# N569S register map
File version: 1.0
Registers are 32-bit, read-write, reset 0x0 unless marked. A register's access mark holds for its fields unless they carry their own. Offsets are from the block's base; [hi:lo] are bit positions.

## UART0 — UART0 Register Map
Base 0x40060000
0x00 UART_DAT ro reset not defined — UART0 Receive/Transmit FIFO Register.
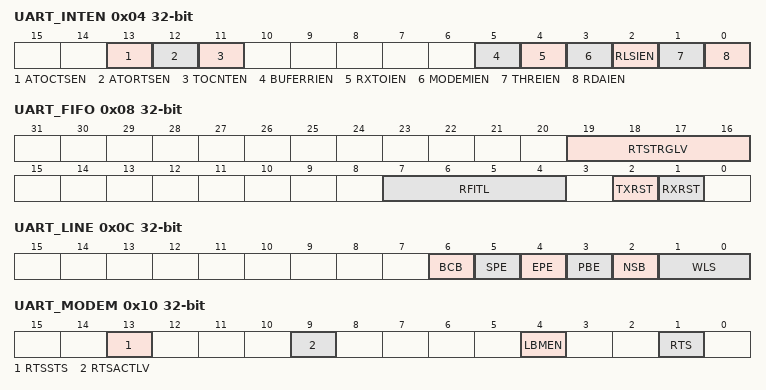
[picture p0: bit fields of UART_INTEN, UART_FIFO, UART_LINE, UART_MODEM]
0x04 UART_INTEN — UART0 Interrupt Enable Register.
  [13] ATOCTSEN — CTS Auto Flow Control Enable. When CTS auto-flow is enabled, the UART will send data to external device when CTS input is asserted (UART will not send data to device until CTS is asserted).
    0=Disable CTS auto flow control; 1=Enable
  [12] ATORTSEN — RTS Auto Flow Control Enable. When RTS auto-flow is enabled, if the number of bytes in the Rx FIFO equals UART_FIFO.RTSTRGLV, the UART will de-assert the RTS signal.
    0=Disable RTS auto flow control; 1=Enable
  [11] TOCNTEN — Time-out Counter Enable
    0=Disable Time-out counter; 1=Enable
  [5] BUFERRIEN — Buffer Error Interrupt Enable
    0=Mask off BUFERRINT; 1=Enable IBUFERRINT
  [4] RXTOIEN — Receive Time Out Interrupt Enable
    0=Mask off RXTOINT; 1=Enable RXTOINT
  [3] MODEMIEN — Modem Status Interrupt Enable
    0=Mask off MODEMINT; 1=Enable MODEMINT
  [2] RLSIEN — Receive Line Status Interrupt Enable
    0=Mask off RLSINT; 1=Enable RLSINT
  [1] THREIEN — Transmit FIFO Register Empty Interrupt Enable
    0=Mask off THERINT; 1=Enable THERINT
  [0] RDAIEN — Receive Data Available Interrupt Enable
    0=Mask off RDAINT; 1=Enable RDAINT
0x08 UART_FIFO — UART0 FIFO Control Register.
  [19:16] RTSTRGLV — RTS Trigger Level for Auto-flow Control
  [7:4] RFITL — Receive FIFO Interrupt (RDAINT) Trigger Level
  [2] TXRST — Transmit FIFO Reset. When TXRST is set, all the bytes in the transmit FIFO are cleared and transmit internal state machine is reset. Note: This bit will auto-clear after 3 UART engine clock cycles.
    0=Writing 0 to this bit has no effect; 1=Writing 1 to this bit will reset the transmit internal state machine and pointers
  [1] RXRST — Receive FIFO Reset. When RXRST is set, all the bytes in the receive FIFO are cleared and receive internal state machine is reset. Note: This bit will auto-clear after 3 UART engine clock cycles.
    0=Writing 0 to this bit has no effect; 1=Writing 1 to this bit will reset the receiving internal state machine and pointers
0x0C UART_LINE — UART0 Line Control Register.
  [6] BCB — Break Control Bit. When this bit is set to logic 1, the serial data output (Tx) is forced to the 'Space' state (logic 0). Normal condition is serial data output is 'Mark' state. This bit acts only on Tx and has no effect on the transmitter logic.
  [5] SPE — Stick Parity Enable
    0=Disable stick parity; 1=When bits PBE and SPE are set 'Stick Parity' is enabled. If EPE=0 the parity bit is transmitted and checked as always set, if EPE=1, the parity bit is transmitted and checked as always cleared
  [4] EPE — Even Parity Enable. This bit has effect only when PBE (parity bit enable) is set.
    0=Odd number of logic 1's are transmitted or checked in the data word and parity bits; 1=Even number of logic 1's are transmitted or checked in the data word and parity bits
  [3] PBE — Parity Bit Enable
    0=Parity bit is not generated (transmit data) or checked (receive data) during transfer; 1=Parity bit is generated or checked between the "last data word bit" and "stop bit" of the serial data
  [2] NSB — Number of STOP bits
    0=One "STOP bit" is generated after the transmitted data; 1=Two "STOP bits" are generated when 6-, 7- and 8-bit word length is selected; One and a half "STOP bits" are generated in the transmitted data when 5-bit word length is selected;
  [1:0] WLS — Word Length Select
0x10 UART_MODEM — UART0 Modem Control Register.
  [13] RTSSTS ro — RTS Pin State (Read Only). This bit is the pin status of RTS.
  [9] RTSACTLV — Request-to-send (RTS) Active Trigger Level. This bit can change the RTS trigger level.
    0=RTS is active low level; 1=RTS is active high level
  [4] LBMEN — Loopback Mode Enable
    0=Disable; 1=Enable
  [1] RTS — RTS (Request-to-send) Signal
    0=Drive RTS inactive ( = ~RTSACTLV); 1=Drive RTS active ( = RTSACTLV)
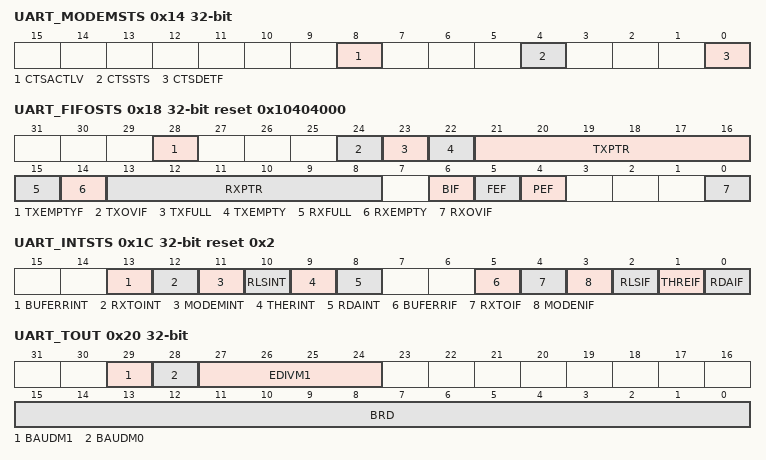
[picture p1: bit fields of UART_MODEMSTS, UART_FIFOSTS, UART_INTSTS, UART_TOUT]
0x14 UART_MODEMSTS — UART0 Modem Status Register.
  [8] CTSACTLV — Clear-to-send (CTS) Active Trigger Level. This bit can change the CTS trigger level.
    0=CTS is active low level; 1=CTS is active high level
  [4] CTSSTS ro — CTS Pin Status (Read Only). This bit is the pin status of CTS.
  [0] CTSDETF — Detect CTS State Change Flag. NOTE: This bit is cleared by writing 1 to itself.
0x18 UART_FIFOSTS reset 0x10404000 — UART0 FIFO Status Register.
  [28] TXEMPTYF ro — Transmitter Empty (Read Only). Bit is set by hardware when Tx FIFO is empty and the STOP bit of the last byte has been transmitted. Bit is cleared automatically when Tx FIFO is not empty or the last byte transmission has not completed. NOTE: This bit is read only.
  [24] TXOVIF — Tx Overflow Error Interrupt Flag. If the Tx FIFO (UART_DAT) is full, an additional write to UART_DAT will cause an overflow condition and set this bit to logic 1. It will also generate a BUFERRIF event and interrupt if enabled. NOTE: This bit is cleared by writing 1 to itself.
  [23] TXFULL ro — Transmit FIFO Full (Read Only). This bit indicates whether the Tx FIFO is full or not.
  [22] TXEMPTY ro — Transmit FIFO Empty (Read Only). This bit indicates whether the Tx FIFO is empty or not. When the last byte of Tx FIFO has been transferred to Transmitter Shift Register, hardware sets this bit high. It will be cleared after writing data to FIFO (Tx FIFO not empty).
  [21:16] TXPTR ro — Tx FIFO Pointer (Read Only). This field returns the Tx FIFO buffer pointer. When CPU writes a byte into the Tx FIFO, TXPTR is incremented. When a byte from Tx FIFO is transferred to the Transmit Shift Register, TXPTR is decremented.
  [15] RXFULL ro — Receive FIFO Full (Read Only). This bit indicates whether the Rx FIFO is full or not. This bit is set when Rx FIFO is full; otherwise it is cleared by hardware.
  [14] RXEMPTY ro — Receive FIFO Empty (Read Only). This bit indicates whether the Rx FIFO is empty or not. When the last byte of Rx FIFO has been read by CPU, hardware sets this bit high. It will be cleared when UART receives any new data.
  [13:8] RXPTR ro — Rx FIFO Pointer (Read Only). This field returns the Rx FIFO buffer pointer. It is the number of bytes available for read in the Rx FIFO. When UART receives one byte from external device, RXPTR is incremented. When one byte of Rx FIFO is read by CPU, RXPTR is decremented.
  [6] BIF — Break Interrupt Flag. This bit is set to a logic 1 whenever the receive data input (Rx) is held in the "space" state (logic 0) for longer than a full word transmission time (that is, the total time of start bit + data bits + parity + stop bits). It is reset whenever the CPU writes 1 to this bit.
  [5] FEF — Framing Error Flag. This bit is set to logic 1 whenever the received character does not have a valid "stop bit" (that is, the stop bit following the last data bit or parity bit is detected as a logic 0), and is reset whenever the CPU writes 1 to this bit.
  [4] PEF — Parity Error Flag. This bit is set to logic 1 whenever the received character does not have a valid "parity bit", and is reset whenever the CPU writes 1 to this bit.
  [0] RXOVIF — Rx Overflow Error Interrupt Flag. If the Rx FIFO (UART_DAT) is full, and an additional byte is received by the UART, an overflow condition will occur and set this bit to logic 1. It will also generate a BUFERRIF event and interrupt if enabled. NOTE: This bit is cleared by writing 1 to itself.
0x1C UART_INTSTS reset 0x2 — UART0 Interrupt Status Register.
  [13] BUFERRINT — Buffer Error Interrupt Indicator to Interrupt Controller. Logical AND of UART_INTEN.BUFERRIEN and BUFERRIF.
  [12] RXTOINT — Time Out Interrupt Indicator to Interrupt Controller. Logical AND of UART_INTEN.RXTOIEN and RXTOIF.
  [11] MODEMINT — MODEM Status Interrupt Indicator to Interrupt. Logical AND of UART_INTEN.MODEMIEN and MODENIF.
  [10] RLSINT — Receive Line Status Interrupt Indicator to Interrupt Controller. Logical AND of UART_INTEN.RLSIEN and RLSIF.
  [9] THERINT — Transmit Holding Register Empty Interrupt Indicator to Interrupt Controller. Logical AND of UART_INTEN.THREIEN and THREIF.
  [8] RDAINT — Receive Data Available Interrupt Indicator to Interrupt Controller. Logical AND of UART_INTEN.RDAIEN and RDAIF.
  [5] BUFERRIF ro — Buffer Error Interrupt Flag (Read Only). This bit is set when either the Tx or Rx FIFO overflows (UART_FIFOSTS.TXOVIF or UART_FIFOSTS.RXOVIF is set). When BUFERRIF is set, the serial transfer may be corrupted. If UART_INTEN.BUFERRIEN is enabled a CPU interrupt request will be generated. NOTE: This bit is cleared when both UART_FIFOSTS.TXOVIF and UART_FIFOSTS.RXOVIF are cleared.
  [4] RXTOIF ro — Time Out Interrupt Flag (Read Only). This bit is set when the Rx FIFO is not empty and no activity occurs in the Rx FIFO and the time out counter equal to TOIC. If UART_INTEN.TOUT_IEN is enabled a CPU interrupt request will be generated. NOTE: This bit is read only and user can read FIFO to clear it.
  [3] MODENIF ro — MODEM Interrupt Flag (Read Only). NOTE: This bit is read only and reset when bit UART_MODEMSTS.CTSDETF is cleared by a write 1.
  [2] RLSIF ro — Receive Line Status Interrupt Flag (Read Only). This bit is set when the Rx receive data has a parity, framing or break error (at least one of, UART_FIFOSTS.BIF, UART_FIFOSTS.FEF and UART_FIFOSTS.PEF, is set). If UART_INTEN.RLSIEN is enabled, the RLS interrupt will be generated. NOTE: This bit is read only and reset to 0 when all bits of BIF, FEF and PEF are cleared.
  [1] THREIF ro — Transmit Holding Register Empty Interrupt Flag (Read Only). This bit is set when the last data of Tx FIFO is transferred to Transmitter Shift Register. If UART_INTEN.THREIEN is enabled, the THRE interrupt will be generated. NOTE: This bit is read only and it will be cleared when writing data into the Tx FIFO.
  [0] RDAIF ro — Receive Data Available Interrupt Flag (Read Only). When the number of bytes in the Rx FIFO equals UART_FIFO.RFITL then the RDAIF will be set. If UART_INTEN.RDAIEN is enabled, the RDA interrupt will be generated. NOTE: This bit is read only and it will be cleared when the number of unread bytes of Rx FIFO drops below the threshold level (RFITL).
0x20 UART_TOUT — UART0 Time Out Register
  [29] BAUDM1 — Divider X Enable. Refer to Table 5116 UART Baud Rate Setting Table for more information. NOTE: When in IrDA mode, this bit must disabled.
    0=Disable divider X ( M = 16); 1=Enable divider X (M = EDIVM1+1, with EDIVM1 ≥ 8)
  [28] BAUDM0 — Divider X Equal 1. Refer to Table 5116 UART Baud Rate Setting Table for more information.
  [27:24] EDIVM1 — Divider x
  [15:0] BRD — Baud Rate Divider. Refer to Table 510 for more information.
0x24 UART_BAUD reset 0xF000000 — UART0 Baud Rate Divisor Register
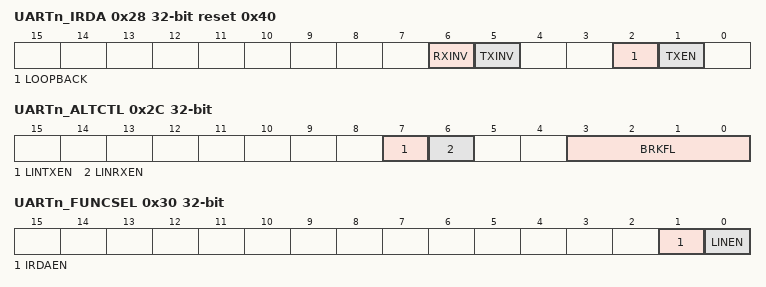
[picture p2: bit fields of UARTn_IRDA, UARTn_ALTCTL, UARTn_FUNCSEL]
0x28 UARTn_IRDA reset 0x40 — UART IrDA Control Register.
  [6] RXINV — Receive Inversion Enable
    0=No inversion; 1=Invert Rx input signal
  [5] TXINV — Transmit Inversion Enable
    0=No inversion; 1=Invert Tx output signal
  [2] LOOPBACK — IrDA Loopback Test Mode. Loopback Tx to Rx.
  [1] TXEN — Transmit/Receive Selection
    0=Enable IrDA receiver; 1=Enable IrDA transmitter
0x2C UARTn_ALTCTL — UART LIN Control Register.
  [7] LINTXEN — LIN TX Break Mode Enable. NOTE: When Tx break field transfer operation finished, this bit will be cleared automatically.
    0=Disable LIN Tx Break Mode; 1=Enable LIN Tx Break Mode
  [6] LINRXEN — LIN RX Enable
    0=Disable LIN Rx mode; 1=Enable LIN Rx mode
  [3:0] BRKFL — UART LIN Break Field Length Count. This field indicates a 4-bit LIN Tx break field count. NOTE: This break field length is BRKFL + 2
0x30 UARTn_FUNCSEL — UART Function Select Register.
  [1] IRDAEN — Enable IrDA Function
    0=UART Function; 1=Enable IrDA Function
  [0] LINEN — Enable LIN Function. Note that IrDA and LIN functions are mutually exclusive: both cannot be active at same time.
    0=UART Function; 1=Enable LIN Function
